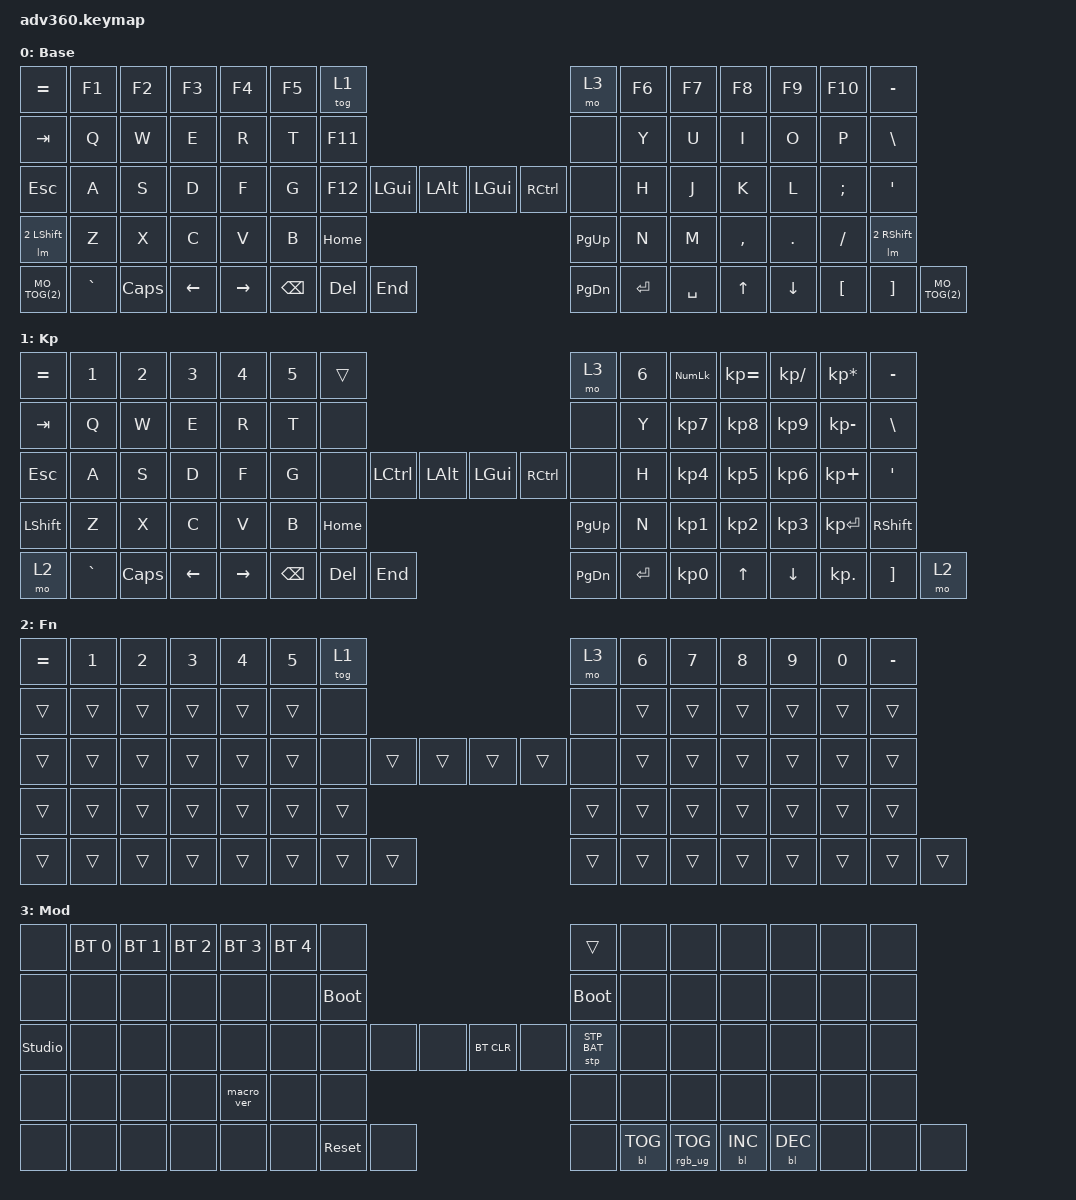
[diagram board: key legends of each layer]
#include <behaviors.dtsi>
#include <dt-bindings/zmk/keys.h>
#include <dt-bindings/zmk/bt.h>
#include <dt-bindings/zmk/rgb.h>
#include <dt-bindings/zmk/stp.h>
#include <dt-bindings/zmk/backlight.h>
#include <dt-bindings/zmk/pointing.h>

#define MO_TOG(layer) &mo_tog layer layer   // Macro to apply momentary-layer-on-hold/toggle-layer-on-tap to a specific layer

/ {
    behaviors {
      #include "macros.dtsi"
      #include "version.dtsi"

      hm: homerow_mods {
          compatible = "zmk,behavior-hold-tap";
          label = "HOMEROW_MODS";
          #binding-cells = <2>;
          tapping-term-ms = <200>;
          quick_tap_ms = <175>;
          flavor = "tap-preferred";
          bindings = <&kp>, <&kp>;
      };

      /**
      * Temporarily switches to a layer (`&mo`) while a modifier is held.
      * Analogous to QMK's `LM()`, using a parameterized macro.
      *
      * Params:
      *  1. Layer to switch to
      *  2. Modifier to press while layer is active
      *
      * Example:
      *  `&lm NUM_LAYER LSHIFT`
      */
       lm: lm {
         compatible = "zmk,behavior-macro-two-param";
         wait-ms = <0>;
         tap-ms = <0>;
         #binding-cells = <2>;
         bindings
         = <&macro_param_1to1>
         , <&macro_press &mo MACRO_PLACEHOLDER>
         , <&macro_param_2to1>
         , <&macro_press &kp MACRO_PLACEHOLDER>
         , <&macro_pause_for_release>
         , <&macro_param_2to1>
         , <&macro_release &kp MACRO_PLACEHOLDER>
         , <&macro_param_1to1>
         , <&macro_release &mo MACRO_PLACEHOLDER>
         ;
       };

       mo_tog: behavior_mo_tog {
            compatible = "zmk,behavior-hold-tap";
            #binding-cells = <2>;
            flavor = "hold-preferred";
            tapping-term-ms = <200>;
            bindings = <&mo>, <&tog>;
        };
    };

  keymap {
    compatible = "zmk,keymap";

    default_layer {
      display-name = "Base";
      bindings = <
        &kp EQUAL &kp F1    &kp F2   &kp F3   &kp F4     &kp F5 &tog 1                                                           &mo 3 &kp F6 &kp F7 &kp F8    &kp F9   &kp F10  &kp MINUS
        &kp TAB   &kp Q     &kp W    &kp E    &kp R      &kp T  &kp F11                                                          &none &kp Y  &kp U  &kp I     &kp O    &kp P    &kp BSLH
        &kp ESC   &kp A     &kp S    &kp D    &kp F      &kp G  &kp F12         &kp LGUI  &kp LALT &kp LGUI  &kp RCTRL           &none &kp H  &kp J  &kp K     &kp L    &kp SEMI &kp SQT
      &lm 2 LSHIFT &kp Z     &kp X    &kp C    &kp V      &kp B                            &kp HOME &kp PG_UP                           &kp N  &kp M  &kp COMMA &kp DOT  &kp FSLH &lm 2 RSHFT
        MO_TOG(2)     &kp GRAVE &kp CAPS &kp LEFT &kp RIGHT                &kp BSPC &kp DEL   &kp END  &kp PG_DN &kp ENTER &kp SPACE              &kp UP &kp DOWN  &kp LBKT &kp RBKT MO_TOG(2)
      >;
    };
    keypad {
      display-name = "Kp";
      bindings = <
        &kp EQUAL &kp N1    &kp N2   &kp N3   &kp N4     &kp N5 &trans                                                           &mo 3 &kp N6 &kp KP_NUM &kp KP_EQUAL &kp KP_DIVIDE &kp KP_MULTIPLY &kp MINUS
        &kp TAB   &kp Q     &kp W    &kp E    &kp R      &kp T  &none                                                            &none &kp Y  &kp KP_N7  &kp KP_N8    &kp KP_N9     &kp KP_MINUS    &kp BSLH
        &kp ESC   &kp A     &kp S    &kp D    &kp F      &kp G  &none           &kp LCTRL &kp LALT &kp LGUI  &kp RCTRL           &none &kp H  &kp KP_N4  &kp KP_N5    &kp KP_N6     &kp KP_PLUS     &kp SQT
        &kp LSHFT &kp Z     &kp X    &kp C    &kp V      &kp B                            &kp HOME &kp PG_UP                           &kp N  &kp KP_N1  &kp KP_N2    &kp KP_N3     &kp KP_ENTER    &kp RSHFT
        &mo 2     &kp GRAVE &kp CAPS &kp LEFT &kp RIGHT                &kp BSPC &kp DEL   &kp END  &kp PG_DN &kp ENTER &kp KP_N0              &kp UP     &kp DOWN     &kp KP_DOT    &kp RBKT        &mo 2
      >;
    };
    fn {
      display-name = "Fn";
      bindings = <
        &kp EQUAL &kp N1    &kp N2   &kp N3   &kp N4     &kp N5 &tog 1                             &mo 3 &kp N6 &kp N7 &kp N8 &kp N9  &kp N0  &kp MINUS
        &trans &trans &trans &trans &trans &trans  &none                                           &none &trans &trans &trans &trans  &trans  &trans
        &trans &trans &trans &trans &trans &trans  &none        &trans &trans &trans &trans        &none &trans &trans &trans &trans  &trans  &trans
        &trans &trans &trans &trans &trans &trans                      &trans &trans                     &trans &trans &trans &trans  &trans  &trans
        &trans &trans &trans &trans &trans               &trans &trans &trans &trans &trans &trans              &trans &trans &trans  &trans  &trans
      >;
    };
    mod {
      display-name = "Mod";
      bindings = <
        &none &bt BT_SEL 0 &bt BT_SEL 1 &bt BT_SEL 2 &bt BT_SEL 3 &bt BT_SEL 4 &none                                                                     &trans                 &none        &none        &none        &none &none &none
        &none &none        &none        &none        &none        &none        &bootloader                                                               &bootloader            &none        &none        &none        &none &none &none
        &studio_unlock &none        &none        &none        &none        &none        &none          &none &none      &bt BT_CLR &none                      &stp STP_BAT &none        &none        &none        &none &none &none
        &none &none        &none        &none        &macro_ver   &none                                      &none      &none                                                        &none        &none        &none        &none &none &none
        &none &none        &none        &none        &none                                  &none &sys_reset &none      &none   &bl BL_TOG  &rgb_ug RGB_TOG              &bl BL_INC   &bl BL_DEC   &none &none &none
      >;
    };
    extra1 { 
      display-name = "Red";    
      status = "reserved";
    };

    extra2 { 
      display-name = "Purple";    
      status = "reserved";
    };

    extra3 { 
      display-name = "Cyan";    
      status = "reserved";
    };

    extra4 { 
      display-name = "Yellow";    
      status = "reserved";
    };
  };
};
